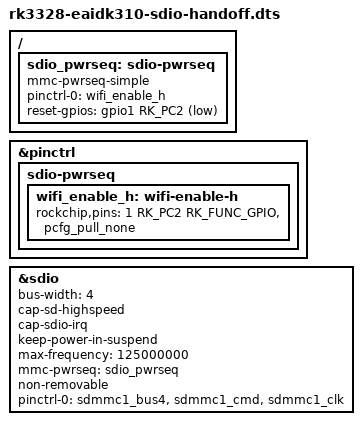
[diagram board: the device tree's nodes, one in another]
// SPDX-License-Identifier: (GPL-2.0+ OR MIT)
/dts-v1/;
#include "rk3328.dtsi"
#include "rk3328-eaidk310-common.dtsi"

/ {
	sdio_pwrseq: sdio-pwrseq {
		compatible = "mmc-pwrseq-simple";
		pinctrl-names = "default";
		pinctrl-0 = <&wifi_enable_h>;
		reset-gpios = <&gpio1 RK_PC2 GPIO_ACTIVE_LOW>;
	};
};

&pinctrl {
	sdio-pwrseq {
		wifi_enable_h: wifi-enable-h {
			rockchip,pins = <1 RK_PC2 RK_FUNC_GPIO &pcfg_pull_none>;
		};
	};
};

&sdio {
	bus-width = <4>;
	cap-sd-highspeed;
	cap-sdio-irq;
	keep-power-in-suspend;
	max-frequency = <125000000>;
	mmc-pwrseq = <&sdio_pwrseq>;
	non-removable;
	pinctrl-names = "default";
	pinctrl-0 = <&sdmmc1_bus4 &sdmmc1_cmd &sdmmc1_clk>;
	status = "okay";
};
